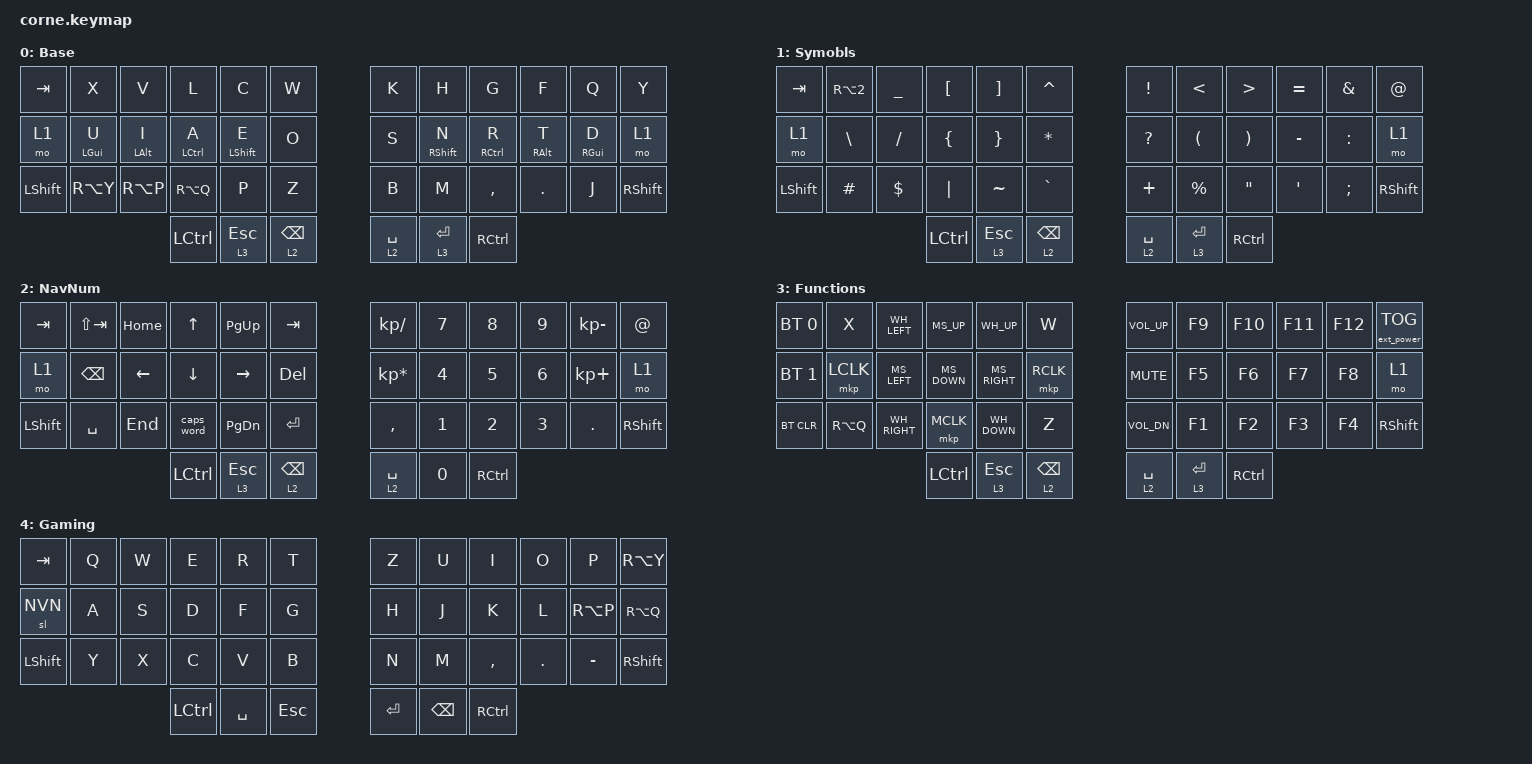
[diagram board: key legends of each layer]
/*
 * Copyright (c) 2020 The ZMK Contributors
 *
 * SPDX-License-Identifier: MIT
 */

#include <behaviors.dtsi>
#include <dt-bindings/zmk/bt.h>
#include <dt-bindings/zmk/ext_power.h>
#include <dt-bindings/zmk/keys.h>

#define BASE  0
#define SYMBOLS 1
#define NVN 2
#define FUNCTIONS 3
#define GAMING 4

#include "includes/mods.dtsi"
#include "includes/mouse.dtsi"

#define COMBO(NAME, BINDINGS, KEYPOS) \
    combo_##NAME { \
        bindings = <BINDINGS>; \
        key-positions = <KEYPOS>; \
        timeout-ms = <300>; \
    };

&led_strip {
    chain-length = <27>;
};

/ {
	combos {
	    compatible = "zmk,combos";

		COMBO(navnum_layer_left, &tog NVN, 37 24)
		COMBO(navnum_layer_right, &tog NVN, 40 35)
		COMBO(functions_layer_left, &tog FUNCTIONS, 37 12)
		COMBO(functions_layer_right, &tog FUNCTIONS, 40 23)
		COMBO(gaming_layer_left, &tog GAMING, 36 24)
		COMBO(gaming_layer_right, &tog GAMING, 41 35)
	};

    keymap {
        compatible = "zmk,keymap";

        base_layer {
            label = "Base";
            bindings = <
// --------------------------------------------------------------------------------------------------------------------------------------------------------------------------------------
// |     TAB     |      X      |      V      |      L      |      C      |      W      |            |      K      |      H      |      G      |      F      |      Q      |      Y      |
// |     LS1     |      U      |      I      |      A      |      E      |      O      |            |      S      |      N      |      R      |      T      |      D      |     LS1     |
// |    SHIFT    |      Ü      |      Ö      |      Ä      |      P      |      Z      |            |      B      |      M      |      ,      |      .      |      J      |    SHIFT    |
//                                           |    CTRL     |   LT3 ESC   |   LT2 BKSP  |            |  LT2 SPC    |   LT3 RET   |    CTRL     |

     &kp TAB       &kp X         &kp V         &kp L         &kp C         &kp W                      &kp K         &kp H         &kp G         &kp F         &kp Q         &kp Y
     &mo 1         &hml LGUI U   &hml LALT I   &hml LCTRL A  &hmlq LSHFT E &kp O                      &kp S         &hmrq RSHFT N &hmr RCTRL R  &hmr RALT T   &hmr RGUI D   &mo 1
     &kp LSHFT     &kp RA(Y)     &kp RA(P)     &kp RA(Q)     &kp P         &kp Z                      &kp B         &kp M         &kp COMMA     &kp DOT       &kp J         &kp RSHFT
                                               &kp LCTRL     &ltl 3 ESC    &ltl 2 BKSP                &ltr 2 SPC    &ltr 3 RET    &kp RCTRL
            >;
        };

        symbols_layer {
            label = "Symobls";
            bindings = <
// --------------------------------------------------------------------------------------------------------------------------------------------------------------------------------------
// |     TAB     |      ²      |      _      |      [      |      ]      |      ^      |            |      !      |      <      |      >      |      =      |      &      |      @      |
// |     LS1     |      \      |      /      |      {      |      }      |      *      |            |      ?      |      (      |      )      |      -      |      :      |     LS1     |
// |    SHIFT    |      #      |      $      |      |      |      ~      |      `      |            |      +      |      %      |      "      |      '      |      ;      |    SHIFT    |
//                                           |    CTRL     |   LT3 ESC   |   LT2 BKSP  |            |   LT2 SPC   |   LT3 RET   |    CTRL     |

     &kp TAB       &kp RA(N2)    &kp UNDER     &kp LBKT      &kp RBKT      &kp CARET                  &kp EXCL      &kp LT        &kp GT        &kp EQUAL     &kp AMPS      &kp AT
     &mo 1         &kp BSLH      &kp FSLH      &kp LBRC      &kp RBRC      &kp ASTRK                  &kp QMARK     &kp LPAR      &kp RPAR      &kp MINUS     &kp COLON     &mo 1
     &kp LSHFT     &kp HASH      &kp DLLR      &kp PIPE      &kp TILDE     &kp GRAVE                  &kp PLUS      &kp PRCNT     &kp DQT       &kp SQT       &kp SEMI      &kp RSHFT
                                               &kp LCTRL     &ltl 3 ESC    &ltl 2 BKSP                &ltr 2 SPC    &ltr 3 RET    &kp RCTRL
                        >;
        };

        navnum_layer {
            label = "NavNum";
            bindings = <
// --------------------------------------------------------------------------------------------------------------------------------------------------------------------------------------
// |     TAB     | SHIFT + TAB |    HOME     |     UP      |   PAGE_UP   |     TAB     |            |      /      |      7      |      8      |      9      |      -      |      @      |
// |     LS1     |    BAKSP    |    LEFT     |    DOWN     |    RIGHT    |     DEL     |            |      *      |      4      |      5      |      6      |      +      |     LS1     |
// |    SHIFT    |     SPC     |    END      |  CAPS WORD  |  PAGE_DOWN  |     ENT     |            |      ,      |      1      |      2      |      3      |      .      |    SHIFT    |
//                                           |    CTRL     |   LT3 ESC   |   LT2 BKSP  |            |   LT2 SPC   |      0      |    CTRL     |

     &kp TAB       &kp LS(TAB)   &kp HOME      &kp UP        &kp PG_UP     &kp TAB                    &kp KP_DIVIDE   &kp N7      &kp N8        &kp N9        &kp KP_MINUS  &kp AT
     &mo 1         &kp BKSP      &kp LEFT      &kp DOWN      &kp RIGHT     &kp DEL                    &kp KP_MULTIPLY &kp N4      &kp N5        &kp N6        &kp KP_PLUS   &mo 1
     &kp LSHFT     &kp SPC       &kp END       &caps_word    &kp PG_DN     &kp RET                    &kp COMMA       &kp N1      &kp N2        &kp N3        &kp DOT       &kp RSHFT
                                               &kp LCTRL     &ltl 3 ESC    &ltl 2 BKSP                &ltr 2 SPC      &kp N0      &kp RCTRL
	        >;
        };

        functions_layer {
            label = "Functions";
            bindings = <
// --------------------------------------------------------------------------------------------------------------------------------------------------------------------------------------
// |     BT1     |      X      | 3 RET WH LT |  MOUSE UP   | MOUSE WH UP |     W       |            |  VOLUME UP  |     F9      |     F10     |    F11      |     F12     | POWER_TGGLE |
// |     BT2     |  LEFT MBT   | MOUSE LEFT  | MOUSE DOWN  | MOUSE RIGHT |  RIGHT MBT  |            |     MUTE    |     F5      |     F6      |    F7       |     F8      |     LS1     |
// |     BT3     |      Ü      | MOUSE WH RT | MIDDLE MBT  | MOUSE WH DN |     Z       |            | VOLUME DOWN |     F1      |     F2      |    F3       |     F4      |    SHIFT    |
//                                           |    CTRL     |    LT3 ESC  |   LT2 BKSP  |            |  LT2 SPC    |   LT3 RET   |    CTRL     |

     &bt BT_SEL 0  &kp X         WH_LEFT       MS_UP         WH_UP         &kp W                      &kp C_VOL_UP  &kp F9        &kp F10        &kp F11       &kp F12       &ext_power EP_TOG
     &bt BT_SEL 1  &mkp LCLK     MS_LEFT       MS_DOWN       MS_RIGHT      &mkp RCLK                  &kp C_MUTE    &kp F5        &kp F6         &kp F7        &kp F8        &mo 1
     &bt BT_CLR    &kp RA(Q)     WH_RIGHT      &mkp MCLK     WH_DOWN       &kp Z                      &kp C_VOL_DN  &kp F1        &kp F2         &kp F3        &kp F4        &kp RSHFT
                                               &kp LCTRL     &ltl 3 ESC    &ltl 2 BKSP                &ltr 2 SPC    &ltr 3 RET    &kp RCTRL
            >;
        };


        gaming_layer {
            label = "Gaming";
            bindings = <
// --------------------------------------------------------------------------------------------------------------------------------------------------------------------------------------
// |     TAB     |      Q      |      W      |      E      |      R      |      T      |            |      Z      |      U      |      I      |      O      |      P      |      ü      |
// |     LS2     |      A      |      S      |      D      |      F      |      G      |            |      H      |      J      |      K      |      L      |      ö      |      ä      |
// |    SHIFT    |      Y      |      X      |      C      |      V      |      B      |            |      N      |      M      |      ,      |      .      |      -      |    SHIFT    |
//                                           |    CTRL     |     SPC     |     ESC     |            |     ENT     |    BKSP     |    CTRL     |

     &kp TAB       &kp Q         &kp W         &kp E         &kp R         &kp T                      &kp Z         &kp U         &kp I         &kp O         &kp P         &kp RA(Y)
     &sl NVN       &kp A         &kp S         &kp D         &kp F         &kp G                      &kp H         &kp J         &kp K         &kp L         &kp RA(P)     &kp RA(Q)
     &kp LSHFT     &kp Y         &kp X         &kp C         &kp V         &kp B                      &kp N         &kp M         &kp COMMA     &kp DOT       &kp MINUS     &kp RSHFT
                                               &kp LCTRL     &kp SPC       &kp ESC                    &kp RET       &kp BKSP      &kp RCTRL
            >;
        };
	};
};
